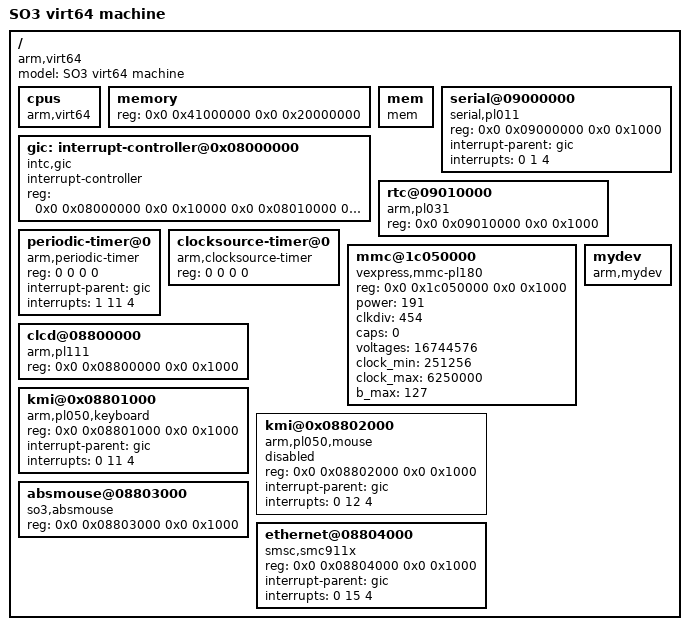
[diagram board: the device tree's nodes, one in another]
/*
 * Copyright (C) 2014-2019 Daniel Rossier <daniel.rossier@heig-vd.ch>
 * 
 * This program is free software; you can redistribute it and/or modify
 * it under the terms of the GNU General Public License version 2 as
 * published by the Free Software Foundation.
 *
 * This program is distributed in the hope that it will be useful,
 * but WITHOUT ANY WARRANTY; without even the implied warranty of
 * MERCHANTABILITY or FITNESS FOR A PARTICULAR PURPOSE.  See the
 * GNU General Public License for more details.
 *
 * You should have received a copy of the GNU General Public License
 * along with this program; if not, write to the Free Software
 * Foundation, Inc., 51 Franklin St, Fifth Floor, Boston, MA  02110-1301  USA
 *
 */
 
/dts-v1/;

/ {
	model = "SO3 virt64 machine";
	compatible = "arm,virt64";
	
	#address-cells = <2>;
	#size-cells = <2>;
	
	cpus {
		device_type = "cpu";
		compatible = "arm,virt64";
	};
	
	memory {
		device_type = "memory";
		reg = <0x0 0x41000000 0x0 0x20000000>; /* 512 MB */
	};

	mem {
		compatible = "mem";
		status = "ok";
	};

	/* GIC interrupt controller */
	gic:interrupt-controller@0x08000000 {
		compatible = "intc,gic";
		interrupt-controller;
		#interrupt-cells = <3>;
		
		/* GIC dist, cpu, hyp */
		reg = <0x0 0x08000000 0x0 0x10000
		       0x0 0x08010000 0x0 0x10000>;
		
		status = "ok";
	};
 
	/* virt64 console UART */
	serial@09000000 {
		compatible = "serial,pl011";
		reg = <0x0 0x09000000 0x0 0x1000>;
		interrupt-parent = <&gic>;
		interrupts = <0 1 4>;
		status = "ok";
	};

	/* Real-time clock (PL031), seeded from the host wall-clock by QEMU */
	rtc@09010000 {
		compatible = "arm,pl031";
		reg = <0x0 0x09010000 0x0 0x1000>;
		status = "ok";
	};

	/* Periodic timer based on ARM CP15 timer */
	periodic-timer@0 {
		compatible = "arm,periodic-timer";
		reg = <0 0 0 0>;
		interrupt-parent = <&gic>;
		interrupts = <1 11 4>;
		status = "ok";
	};
	
	/* Clocksource free-running timer based on ARM CP15 timer */
	clocksource-timer@0 {
		compatible = "arm,clocksource-timer";
		reg = <0 0 0 0>;
		status = "ok";
	};
	
	/* MMC */
	mmc@1c050000 {
		compatible = "vexpress,mmc-pl180";
		reg = <0x0 0x1c050000 0x0 0x1000>;
		power = <191>;
		clkdiv = <454>;
		caps = <0>;
		voltages = <16744576>;
		clock_min = <251256>;
		clock_max = <6250000>;
		b_max = <127>;

		status = "ok";
	};

	mydev {
		compatible = "arm,mydev";
		status = "ok";
	};

	/* PL111 Color LCD Controller
	 *   http://infocenter.arm.com/help/index.jsp?topic=/com.arm.doc.ddi0293c/index.html
	 */
	clcd@08800000{
		compatible = "arm,pl111";
		reg = <0x0 0x08800000 0x0 0x1000>;

		status = "ok";
	};

	/* PL050 PS2 Keyboard/Mouse Interface
	 *   http://infocenter.arm.com/help/index.jsp?topic=/com.arm.doc.ddi0143c/index.html
	 */
	kmi@0x08801000 { /* keyboard */
		compatible = "arm,pl050,keyboard";
		reg = <0x0 0x08801000 0x0 0x1000>;
		interrupt-parent = <&gic>;
		/* SPI 11 — matches the so3 QEMU patch irqmap[VIRT_KMI0]=11
		 * (hw/arm/virt.c). Was 36 (a vexpress-era number) that QEMU
		 * never raises here, so keyboard events were silently lost. */
		interrupts = <0 11 4>;

		status = "ok";
	};

	/* PL050 PS2 Keyboard/Mouse Interface
	 *   http://infocenter.arm.com/help/index.jsp?topic=/com.arm.doc.ddi0143c/index.html
	 */
	kmi@0x08802000 { /* mouse */
		compatible = "arm,pl050,mouse";
		reg = <0x0 0x08802000 0x0 0x1000>;

		interrupt-parent = <&gic>;
		/* SPI 12 — matches the so3 QEMU patch irqmap[VIRT_KMI1]=12
		 * (hw/arm/virt.c). Was 37 (vexpress-era) that QEMU never raises
		 * here, so mouse events were silently lost. */
		interrupts = <0 12 4>;

		/* Disabled: superseded by the absolute pointer below. The PL050
		 * mouse is RELATIVE, which forces QEMU into pointer-grab/warp mode
		 * (broken under Wayland, and prone to host/guest drift). Re-enable
		 * (and disable absmouse) only if you specifically need the
		 * relative PS/2 path. */
		status = "disabled";
	};

	/* SO3 absolute pointer — polled MMIO device fed by QEMU's absolute
	 * input handler (so3 QEMU patch, VIRT_ABSMOUSE @ 0x08803000). Reports
	 * absolute coordinates, so the guest cursor maps 1:1 to the host
	 * pointer with no grab/warp/drift. Owns /dev/mouse (DEV_CLASS_MOUSE). */
	absmouse@08803000 {
		compatible = "so3,absmouse";
		reg = <0x0 0x08803000 0x0 0x1000>;

		status = "ok";
	};
	
	/* SMSC LAN9118 Ethernet MAC (so3 QEMU patch, VIRT_ETH @ 0x08804000).
	 * QEMU's stock 'virt' machine has no Ethernet controller SO3 can drive —
	 * only virtio-net — so the machine model adds one next to the other SO3
	 * devices. Not at the 0x1a000000 vexpress-a15 uses: that address falls
	 * inside the PCIe MMIO window, whose gpex alias shadows anything mapped
	 * underneath it. */
	ethernet@08804000 {
		compatible = "smsc,smc911x";
		reg = <0x0 0x08804000 0x0 0x1000>;

		interrupt-parent = <&gic>;
		/* SPI 15 — matches irqmap[VIRT_ETH] in the so3 QEMU patch. */
		interrupts = <0 15 4>;

		status = "ok";
	};
    	
};
